# STM32WL3R register map
File version: 1.0
CPU: CM0+ r0p0, little endian, MPU, no FPU, 4 interrupt priority bits
Registers are 32-bit, read-write, reset 0x0 unless marked. A register's access mark holds for its fields unless they carry their own. Offsets are from the block's base; [hi:lo] are bit positions; {n}, {i} and the like mark numbered series.

## SYSCFG — SYSCFG address block description
Base 0x40000000
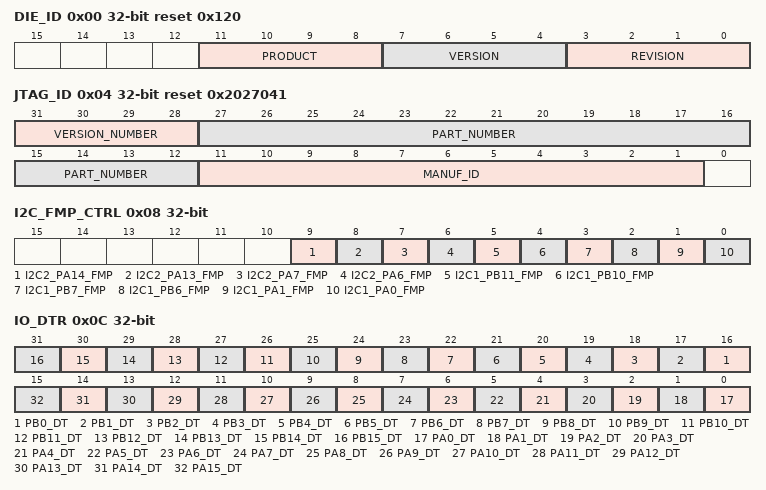
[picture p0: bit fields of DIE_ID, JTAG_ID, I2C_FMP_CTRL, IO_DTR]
0x00 DIE_ID ro reset 0x120
  [11:8] PRODUCT — Product version.
  [7:4] VERSION — Cut version
  [3:0] REVISION — Cut revision (metal fix)
0x04 JTAG_ID ro reset 0x2027041
  [31:28] VERSION_NUMBER — Version
  [27:12] PART_NUMBER
  [11:1] MANUF_ID — Manufacturer ID
0x08 I2C_FMP_CTRL
  [9] I2C2_PA14_FMP — I2C2_PA14_FMP: I2C2 Fast-Mode Plus driving capability for I2C2_SDA on PA14 I/O.
  [8] I2C2_PA13_FMP — I2C2_PA13_FMP: I2C2 Fast-Mode Plus driving capability for I2C2_SCL on PA13 I/O.
  [7] I2C2_PA7_FMP — I2C2_PA7_FMP: I2C2 Fast-Mode Plus driving capability for I2C2_SDA on PA7 I/O.
  [6] I2C2_PA6_FMP — I2C2_PA6_FMP: I2C2 Fast-Mode Plus driving capability for I2C2_SCL on PA6 I/O.
  [5] I2C1_PB11_FMP — I2C1_PB11_FMP: I2C1 Fast-Mode Plus driving capability for I2C1_SCL on PB11 I/O.
  [4] I2C1_PB10_FMP — I2C1_PB10_FMP: I2C1 Fast-Mode Plus driving capability for I2C1_SDA on PB10 I/O.
  [3] I2C1_PB7_FMP — I2C1 Fast-Mode Plus driving capability for I2C1_SDA on PB7 I/O.
  [2] I2C1_PB6_FMP — I2C1 Fast-Mode Plus driving capability for I2C1_SCL on PB6 I/O.
  [1] I2C1_PA1_FMP — I2C1 Fast-Mode Plus driving capability for I2C1_SDA on PA1 I/O.
  [0] I2C1_PA0_FMP — I2C1 Fast-Mode Plus driving capability for I2C1_SCL on PA0 I/O.
0x0C IO_DTR
  [n+16] PB{n}_DT (n=0..15) — PB{n}_DT: Interrupt Detection Type for port B I/Os.
  [n] PA{n}_DT (n=0..15) — PA{n}_DT: Interrupt Detection Type for port A I/Os.
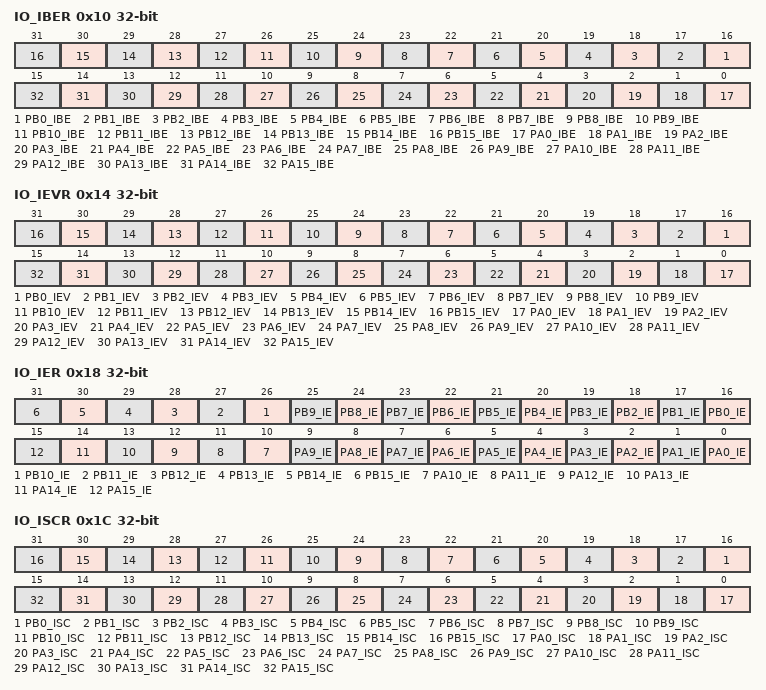
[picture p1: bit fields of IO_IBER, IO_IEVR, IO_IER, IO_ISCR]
0x10 IO_IBER
  [n+16] PB{n}_IBE (n=0..15) — PB{n}_IBE: Interrupt edge selection for port B I/Os.
  [n] PA{n}_IBE (n=0..15) — PA{n}_IBE: Interrupt edge selection for Port A I/Os.
0x14 IO_IEVR
  [n+16] PB{n}_IEV (n=0..15) — PB{n}_IEV : Interrupt polarity event for Port B I/Os.
  [n] PA{n}_IEV (n=0..15) — PA{n}_IEV : Interrupt polarity event for Port A I/Os.
0x18 IO_IER
  [n+16] PB{n}_IE (n=0..15) — PB{n}_IE: Interrupt enable for port B I/Os.
  [n] PA{n}_IE (n=0..15) — PA{n}_IE: Interrupt enable for port A I/Os.
0x1C IO_ISCR
  [n+16] PB{n}_ISC (n=0..15) — PB{n}_ISC: Interrupt status (before mask) for port B I/Os.
  [n] PA{n}_ISC (n=0..15) — PA{n}_ISC: Interrupt status (before mask) for port a I/Os.
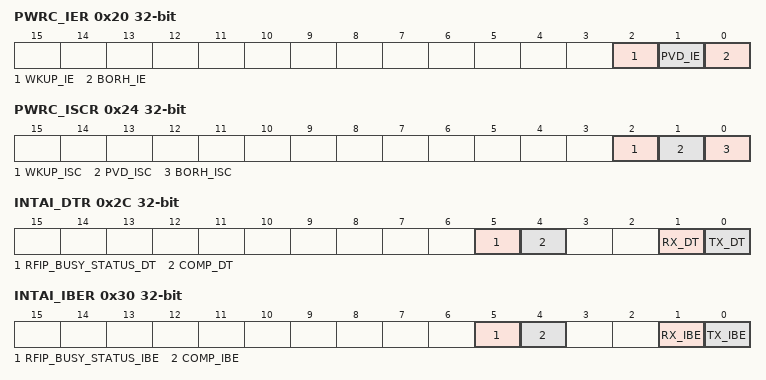
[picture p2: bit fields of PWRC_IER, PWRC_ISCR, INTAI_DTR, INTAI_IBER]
0x20 PWRC_IER
  [2] WKUP_IE — WKUP_IE: Power Controller Wakeup event interrupt enable.
  [1] PVD_IE — PVD_IE: Programmable Voltage Detector interrupt enable.
  [0] BORH_IE — BORH_IE: BORH interrupt enable.
0x24 PWRC_ISCR
  [2] WKUP_ISC — WKUP_ISC: Indicates the Power Controller receives a Wakeup event.
  [1] PVD_ISC — PVD_ISC: Programmable Voltage Detector status.
  [0] BORH_ISC — BORH_ISC: BORH interrupt status.
0x28 GPIO_SWA_CTRL
  [0] ATB1_nPVD — ATB1_nPVD: select the analog feature on PB14 between ATB1 and PVD when the PB14 I/O
0x2C INTAI_DTR
  [5] RFIP_BUSY_STATUS_DT — RFIP_BUSY_STATUS_DT: detection type on RFIP_BUSY_STATUS signal:
  [4] COMP_DT — COMP_DT: detection type on COMP_OUT (after COMP_POL selection) signal:
  [1] RX_DT — RX_DT: detection type on RX_SEQUENCE signal:
  [0] TX_DT — TX_DT: detection type on TX_SEQUENCE signal:
0x30 INTAI_IBER
  [5] RFIP_BUSY_STATUS_IBE — RFIP_BUSY_STATUS_IBE: interrupt edge register on RFIP_BUSY_STATUS signal:
  [4] COMP_IBE — COMP_IBE: interrupt edge register on COMP_OUT signal:
  [1] RX_IBE — RX_IBE: interrupt edge register on RX_SEQUENCE signal:
  [0] TX_IBE — TX_IBE: interrupt edge register on TX_SEQUENCE signal:
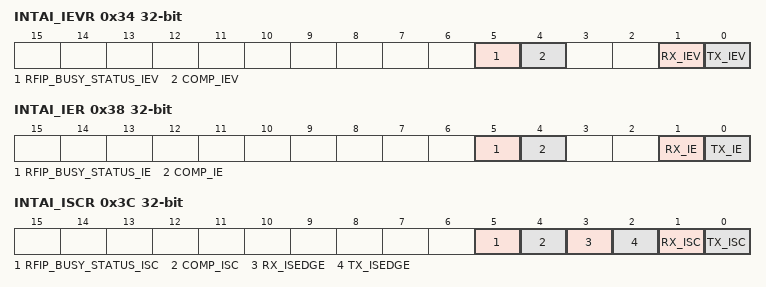
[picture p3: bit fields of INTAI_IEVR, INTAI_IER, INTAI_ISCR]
0x34 INTAI_IEVR
  [5] RFIP_BUSY_STATUS_IEV — RFIP_BUSY_STATUS_IEV: interrupt polarity event on RFIP_BUSY_STATUS signal:
  [4] COMP_IEV — COMP_IEV: interrupt polarity event on COMP_OUT signal:
  [1] RX_IEV — RX_IEV: interrupt polarity event on RX_SEQUENCE signal:
  [0] TX_IEV — TX_IEV: interrupt polarity event on TX_SEQUENCE signal:
0x38 INTAI_IER
  [5] RFIP_BUSY_STATUS_IE — RFIP_BUSY_STATUS_IE: interrupt enable on RFIP_BUSY_STATUS signal:
  [4] COMP_IE — COMP_IE: interrupt enable on COMP_OUT signal:
  [1] RX_IE — RX_IE: interrupt enable on RX_SEQUENCE signal:
  [0] TX_IE — TX_IE: interrupt enable on TX_SEQUENCE signal:
0x3C INTAI_ISCR
  [5] RFIP_BUSY_STATUS_ISC — RFIP_BUSY_STATUS_ISC: interrupt status on RFIP_BUSY_STATUS (can be a rising or a
  [4] COMP_ISC — COMP_ISC: interrupt status on COMP_OUT (can be a rising or a falling edge depending on
  [3] RX_ISEDGE ro — RX_ISEDGE: interrupt edge status on RX_SEQUENCE signal:
  [2] TX_ISEDGE ro — TX_ISEDGE: interrupt edge status on TX_SEQUENCE signal:
  [1] RX_ISC — RX_ISC: interrupt status on RX_SEQUENCE signal (can be a rising or a falling edge
  [0] TX_ISC — TX_ISC:interrupt status on TX_SEQUENCE signal (can be a rising or a falling edge
0x40 SYSCFG_SR1 ro
  [5] RFIP_BUSY_STATUS — RFIP_BUSY_STATUS: MR_SUBG BUSY status:
0x44 RF_DTB_CONFIG
  [1:0] RF_DTB_CONFIG — Controlling AF7 extended mode:
